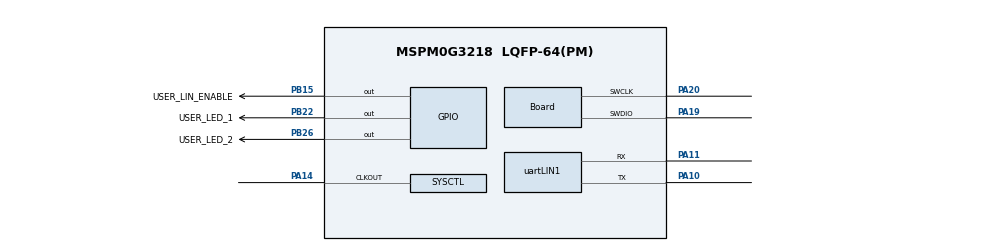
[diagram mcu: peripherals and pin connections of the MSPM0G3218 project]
//@cliArgs --device "MSPM0G321X" --package "LQFP-64(PM)" --part "Default"
//@v2CliArgs --device "MSPM0G3218" --package "LQFP-64(PM)"
// @cliArgs --board /ti/boards/LP_MSPM0G3218 --rtos nortos

/**
 * Import the modules used in this configuration.
 */
const Board    = scripting.addModule("/ti/driverlib/Board");
const GPIO     = scripting.addModule("/ti/driverlib/GPIO", {}, false);
const GPIO1    = GPIO.addInstance();
const GPIO2    = GPIO.addInstance();
const SYSCTL   = scripting.addModule("/ti/driverlib/SYSCTL");
const TIMER    = scripting.addModule("/ti/driverlib/TIMER", {}, false);
const TIMER1   = TIMER.addInstance();
const uartLIN  = scripting.addModule("/ti/driverlib/uartLIN", {}, false);
const uartLIN1 = uartLIN.addInstance();

/**
 * Write custom configuration values to the imported modules.
 */
Board.peripheral.$assign          = "DEBUGSS";
Board.peripheral.swclkPin.$assign = "PA20";
Board.peripheral.swdioPin.$assign = "PA19";

GPIO1.$name                         = "GPIO_LEDS";
GPIO1.associatedPins.create(2);
GPIO1.associatedPins[0].$name       = "USER_LED_1";
GPIO1.associatedPins[0].assignedPin = "ANY";
GPIO1.associatedPins[0].pin.$assign = "PB22";
GPIO1.associatedPins[1].$name       = "USER_LED_2";
GPIO1.associatedPins[1].pin.$assign = "PB26";

GPIO2.$name                         = "GPIO_LIN_ENABLE";
GPIO2.port                          = "PORTB";
GPIO2.portSegment                   = "Lower";
GPIO2.associatedPins[0].$name       = "USER_LIN_ENABLE";
GPIO2.associatedPins[0].assignedPin = "15";
GPIO2.associatedPins[0].pin.$assign = "PB15";

SYSCTL.forceDefaultClkConfig        = true;
SYSCTL.enableEXCLK                  = true;
SYSCTL.peripheral.$assign           = "SYSCTL";
SYSCTL.peripheral.clkOutPin.$assign = "PA14";

TIMER1.$name              = "TIMER_0";
TIMER1.timerClkSrc        = "LFCLK";
TIMER1.interrupts         = ["ZERO"];
TIMER1.peripheral.$assign = "TIMA0";

uartLIN1.$name                            = "LIN_0";
uartLIN1.targetBaudRate                   = 19200;
uartLIN1.enableLinCounter                 = true;
uartLIN1.enableLinCounterClearFallingEdge = true;
uartLIN1.enableLinCountWhileLow           = true;
uartLIN1.tbitVal                          = 9.5;
uartLIN1.enableDMARX                      = false;
uartLIN1.enableDMATX                      = false;
uartLIN1.enableLinCounterCompare          = true;
uartLIN1.enableFIFO                       = true;
uartLIN1.rxFifoThreshold                  = "DL_UART_RX_FIFO_LEVEL_ONE_ENTRY";
uartLIN1.txFifoThreshold                  = "DL_UART_TX_FIFO_LEVEL_EMPTY";
uartLIN1.enabledInterrupts                = ["BREAK_ERROR","LINC0_MATCH","LIN_COUNTER_OVERFLOW","LIN_FALLING_EDGE","OVERRUN_ERROR"];
uartLIN1.peripheral.$assign               = "UC0";
uartLIN1.peripheral.rxPin.$assign         = "PA11";
uartLIN1.peripheral.txPin.$assign         = "PA10";

const ProjectConfig              = scripting.addModule("/ti/project_config/ProjectConfig", {}, false);
ProjectConfig.migrationCondition = true;
